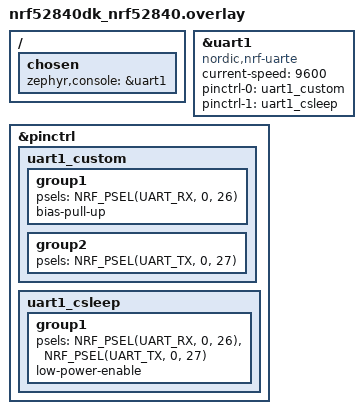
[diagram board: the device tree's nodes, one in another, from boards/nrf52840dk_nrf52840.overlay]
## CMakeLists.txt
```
# SPDX-License-Identifier: Apache-2.0

cmake_minimum_required(VERSION 3.20.0)

find_package(Zephyr REQUIRED HINTS $ENV{ZEPHYR_BASE})
project(hello_world_passthrough_test)

target_sources(app PRIVATE src/main.c)
```

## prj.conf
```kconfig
# nothing here
CONFIG_CONSOLE=y
CONFIG_UART_CONSOLE=y
```

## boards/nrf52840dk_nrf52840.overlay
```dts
/ {
	chosen {
		zephyr,console = &uart1;
	};
};



&uart1 {
	compatible = "nordic,nrf-uarte";
	current-speed = <9600>;
	status = "okay";

	pinctrl-0 = <&uart1_custom>;
	pinctrl-1 = <&uart1_csleep>;
	pinctrl-names = "default", "sleep";
};

&pinctrl {
	uart1_custom: uart1_custom {
		group1 {
			psels = <NRF_PSEL(UART_RX, 0, 26)>;
			bias-pull-up;
		};
		group2 {
			psels = <NRF_PSEL(UART_TX, 0, 27)>;
		};
	};

	uart1_csleep: uart1_csleep {
		group1 {
			psels = <NRF_PSEL(UART_RX, 0, 26)>,
				<NRF_PSEL(UART_TX, 0, 27)>;
			low-power-enable;
		};
	};
};
```

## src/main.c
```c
/*
 * Copyright (c) 2012-2014 Wind River Systems, Inc.
 *
 * SPDX-License-Identifier: Apache-2.0
 */

#include <stdio.h>
#include <zephyr/kernel.h>

int main(void)
{
	int i = 0;
	while(1) {
		printf("Hello World! %d\n", i++);
		k_sleep(K_SECONDS(1));
	}

	return 0;
}
```
